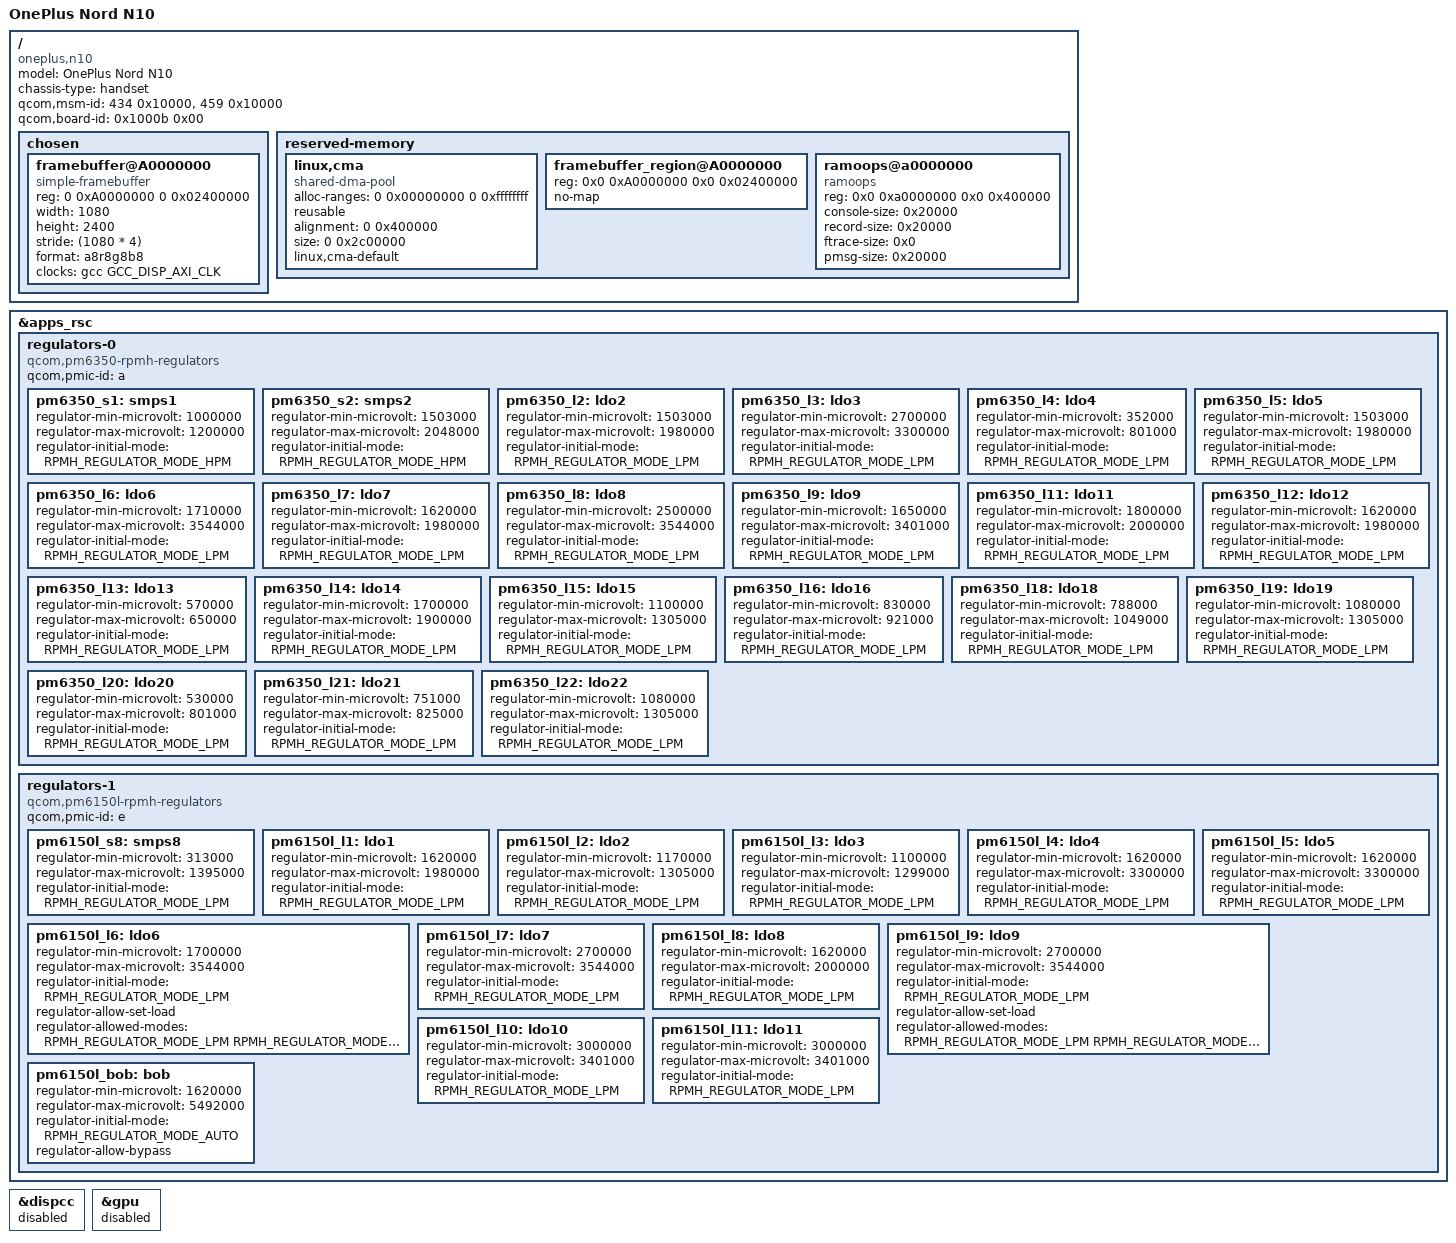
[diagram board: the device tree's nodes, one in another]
// SPDX-License-Identifier: BSD-3-Clause
/*
 * Copyright (c) 2024, Saalim Quadri <saalimquadri2@gmail.com>
 */

/dts-v1/;

#include <dt-bindings/pinctrl/qcom,pmic-gpio.h>
#include <dt-bindings/regulator/qcom,rpmh-regulator.h>
#include "sm6350.dtsi"
#include "pm6350.dtsi"

/ {
	model = "OnePlus Nord N10";
	compatible = "oneplus,n10", "qcom,sm6350", "qcom,lagoon", "qcom,lagoon-qrd", "qcom,qrd";
	chassis-type = "handset";
	qcom,msm-id = <434 0x10000>, <459 0x10000>;
	qcom,board-id = <0x1000b 0x00>;

	chosen {
		#address-cells = <2>;
		#size-cells = <2>;
		ranges;

		framebuffer@A0000000 {
			compatible = "simple-framebuffer";
			reg = <0 0xA0000000 0 0x02400000>;
			width = <1080>;
			height = <2400>;
			stride = <(1080 * 4)>;
			format = "a8r8g8b8";
			clocks = <&gcc GCC_DISP_AXI_CLK>;
		};
	};

	reserved-memory {
		#address-cells = <2>;
		#size-cells = <2>;
		ranges;

		linux,cma {
			compatible = "shared-dma-pool";
			alloc-ranges = <0 0x00000000 0 0xffffffff>;
			reusable;
			alignment = <0 0x400000>;
			size = <0 0x2c00000>;
			linux,cma-default;
		};

		framebuffer_region@A0000000 {
			reg = <0x0 0xA0000000 0x0 0x02400000>;
			no-map;
		};

		ramoops@a0000000 {
			compatible = "ramoops";
			reg = <0x0 0xa0000000 0x0 0x400000>;
			console-size = <0x20000>;
			record-size = <0x20000>;
			ftrace-size = <0x0>;
			pmsg-size = <0x20000>;
		};
	};

};

&apps_rsc {
	regulators-0 {
		compatible = "qcom,pm6350-rpmh-regulators";
		qcom,pmic-id = "a";

		pm6350_s1: smps1 {
			regulator-min-microvolt = <1000000>;
			regulator-max-microvolt = <1200000>;
			regulator-initial-mode = <RPMH_REGULATOR_MODE_HPM>;
		};

		pm6350_s2: smps2 {
			regulator-min-microvolt = <1503000>;
			regulator-max-microvolt = <2048000>;
			regulator-initial-mode = <RPMH_REGULATOR_MODE_HPM>;
		};

		pm6350_l2: ldo2 {
			regulator-min-microvolt = <1503000>;
			regulator-max-microvolt = <1980000>;
			regulator-initial-mode = <RPMH_REGULATOR_MODE_LPM>;
		};

		pm6350_l3: ldo3 {
			regulator-min-microvolt = <2700000>;
			regulator-max-microvolt = <3300000>;
			regulator-initial-mode = <RPMH_REGULATOR_MODE_LPM>;
		};

		pm6350_l4: ldo4 {
			regulator-min-microvolt = <352000>;
			regulator-max-microvolt = <801000>;
			regulator-initial-mode = <RPMH_REGULATOR_MODE_LPM>;
		};

		pm6350_l5: ldo5 {
			regulator-min-microvolt = <1503000>;
			regulator-max-microvolt = <1980000>;
			regulator-initial-mode = <RPMH_REGULATOR_MODE_LPM>;
		};

		pm6350_l6: ldo6 {
			regulator-min-microvolt = <1710000>;
			regulator-max-microvolt = <3544000>;
			regulator-initial-mode = <RPMH_REGULATOR_MODE_LPM>;
		};

		pm6350_l7: ldo7 {
			regulator-min-microvolt = <1620000>;
			regulator-max-microvolt = <1980000>;
			regulator-initial-mode = <RPMH_REGULATOR_MODE_LPM>;
		};

		pm6350_l8: ldo8 {
			regulator-min-microvolt = <2500000>;
			regulator-max-microvolt = <3544000>;
			regulator-initial-mode = <RPMH_REGULATOR_MODE_LPM>;
		};

		pm6350_l9: ldo9 {
			regulator-min-microvolt = <1650000>;
			regulator-max-microvolt = <3401000>;
			regulator-initial-mode = <RPMH_REGULATOR_MODE_LPM>;
		};

		pm6350_l11: ldo11 {
			regulator-min-microvolt = <1800000>;
			regulator-max-microvolt = <2000000>;
			regulator-initial-mode = <RPMH_REGULATOR_MODE_LPM>;
		};

		pm6350_l12: ldo12 {
			regulator-min-microvolt = <1620000>;
			regulator-max-microvolt = <1980000>;
			regulator-initial-mode = <RPMH_REGULATOR_MODE_LPM>;
		};

		pm6350_l13: ldo13 {
			regulator-min-microvolt = <570000>;
			regulator-max-microvolt = <650000>;
			regulator-initial-mode = <RPMH_REGULATOR_MODE_LPM>;
		};

		pm6350_l14: ldo14 {
			regulator-min-microvolt = <1700000>;
			regulator-max-microvolt = <1900000>;
			regulator-initial-mode = <RPMH_REGULATOR_MODE_LPM>;
		};

		pm6350_l15: ldo15 {
			regulator-min-microvolt = <1100000>;
			regulator-max-microvolt = <1305000>;
			regulator-initial-mode = <RPMH_REGULATOR_MODE_LPM>;
		};

		pm6350_l16: ldo16 {
			regulator-min-microvolt = <830000>;
			regulator-max-microvolt = <921000>;
			regulator-initial-mode = <RPMH_REGULATOR_MODE_LPM>;
		};

		pm6350_l18: ldo18 {
			regulator-min-microvolt = <788000>;
			regulator-max-microvolt = <1049000>;
			regulator-initial-mode = <RPMH_REGULATOR_MODE_LPM>;
		};

		pm6350_l19: ldo19 {
			regulator-min-microvolt = <1080000>;
			regulator-max-microvolt = <1305000>;
			regulator-initial-mode = <RPMH_REGULATOR_MODE_LPM>;
		};

		pm6350_l20: ldo20 {
			regulator-min-microvolt = <530000>;
			regulator-max-microvolt = <801000>;
			regulator-initial-mode = <RPMH_REGULATOR_MODE_LPM>;
		};

		pm6350_l21: ldo21 {
			regulator-min-microvolt = <751000>;
			regulator-max-microvolt = <825000>;
			regulator-initial-mode = <RPMH_REGULATOR_MODE_LPM>;
		};

		pm6350_l22: ldo22 {
			regulator-min-microvolt = <1080000>;
			regulator-max-microvolt = <1305000>;
			regulator-initial-mode = <RPMH_REGULATOR_MODE_LPM>;
		};
	};

	regulators-1 {
		compatible = "qcom,pm6150l-rpmh-regulators";
		qcom,pmic-id = "e";

		pm6150l_s8: smps8 {
			regulator-min-microvolt = <313000>;
			regulator-max-microvolt = <1395000>;
			regulator-initial-mode = <RPMH_REGULATOR_MODE_LPM>;
		};

		pm6150l_l1: ldo1 {
			regulator-min-microvolt = <1620000>;
			regulator-max-microvolt = <1980000>;
			regulator-initial-mode = <RPMH_REGULATOR_MODE_LPM>;
		};

		pm6150l_l2: ldo2 {
			regulator-min-microvolt = <1170000>;
			regulator-max-microvolt = <1305000>;
			regulator-initial-mode = <RPMH_REGULATOR_MODE_LPM>;
		};

		pm6150l_l3: ldo3 {
			regulator-min-microvolt = <1100000>;
			regulator-max-microvolt = <1299000>;
			regulator-initial-mode = <RPMH_REGULATOR_MODE_LPM>;
		};

		pm6150l_l4: ldo4 {
			regulator-min-microvolt = <1620000>;
			regulator-max-microvolt = <3300000>;
			regulator-initial-mode = <RPMH_REGULATOR_MODE_LPM>;
		};

		pm6150l_l5: ldo5 {
			regulator-min-microvolt = <1620000>;
			regulator-max-microvolt = <3300000>;
			regulator-initial-mode = <RPMH_REGULATOR_MODE_LPM>;
		};

		pm6150l_l6: ldo6 {
			regulator-min-microvolt = <1700000>;
			regulator-max-microvolt = <3544000>;
			regulator-initial-mode = <RPMH_REGULATOR_MODE_LPM>;
			regulator-allow-set-load;
			regulator-allowed-modes = <RPMH_REGULATOR_MODE_LPM
						   RPMH_REGULATOR_MODE_HPM>;
		};

		pm6150l_l7: ldo7 {
			regulator-min-microvolt = <2700000>;
			regulator-max-microvolt = <3544000>;
			regulator-initial-mode = <RPMH_REGULATOR_MODE_LPM>;
		};

		pm6150l_l8: ldo8 {
			regulator-min-microvolt = <1620000>;
			regulator-max-microvolt = <2000000>;
			regulator-initial-mode = <RPMH_REGULATOR_MODE_LPM>;
		};

		pm6150l_l9: ldo9 {
			regulator-min-microvolt = <2700000>;
			regulator-max-microvolt = <3544000>;
			regulator-initial-mode = <RPMH_REGULATOR_MODE_LPM>;
			regulator-allow-set-load;
			regulator-allowed-modes = <RPMH_REGULATOR_MODE_LPM
						   RPMH_REGULATOR_MODE_HPM>;
		};

		pm6150l_l10: ldo10 {
			regulator-min-microvolt = <3000000>;
			regulator-max-microvolt = <3401000>;
			regulator-initial-mode = <RPMH_REGULATOR_MODE_LPM>;
		};

		pm6150l_l11: ldo11 {
			regulator-min-microvolt = <3000000>;
			regulator-max-microvolt = <3401000>;
			regulator-initial-mode = <RPMH_REGULATOR_MODE_LPM>;
		};

		pm6150l_bob: bob {
			regulator-min-microvolt = <1620000>;
			regulator-max-microvolt = <5492000>;
			regulator-initial-mode = <RPMH_REGULATOR_MODE_AUTO>;
			regulator-allow-bypass;
		};
	};
};

&dispcc {
	status = "disabled";
};

&gpu {
	status = "disabled";
};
